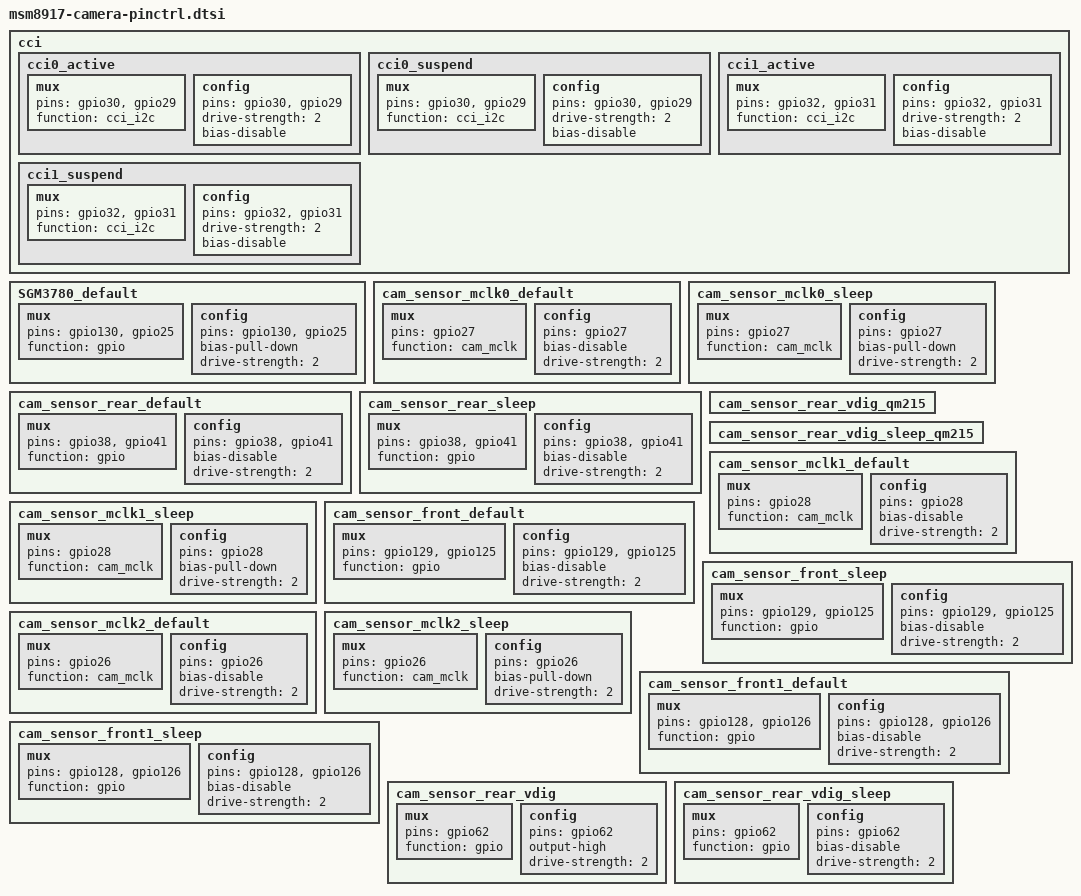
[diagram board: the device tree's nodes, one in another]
/*
 * Copyright (c) 2015, 2018, The Linux Foundation. All rights reserved.
 *
 * This program is free software; you can redistribute it and/or modify
 * it under the terms of the GNU General Public License version 2 and
 * only version 2 as published by the Free Software Foundation.
 *
 * This program is distributed in the hope that it will be useful,
 * but WITHOUT ANY WARRANTY; without even the implied warranty of
 * MERCHANTABILITY or FITNESS FOR A PARTICULAR PURPOSE.  See the
 * GNU General Public License for more details.
 */

cci {
	cci0_active: cci0_active {
		/* cci0 active state */
		mux {
			/* CLK, DATA */
			pins = "gpio30", "gpio29";
			function = "cci_i2c";
		};

		config {
			pins = "gpio30", "gpio29";
			drive-strength = <2>; /* 2 MA */
			bias-disable; /* No PULL */
		};
	};

	cci0_suspend: cci0_suspend {
		/* cci0 suspended state */
		mux {
			/* CLK, DATA */
			pins = "gpio30", "gpio29";
			function = "cci_i2c";
		};

		config {
			pins = "gpio30", "gpio29";
			drive-strength = <2>; /* 2 MA */
			bias-disable; /* No PULL */
		};
	};

	cci1_active: cci1_active {
		/* cci1 active state */
		mux {
			/* CLK, DATA */
			pins = "gpio32", "gpio31";
			function = "cci_i2c";
		};

		config {
			pins = "gpio32", "gpio31";
			drive-strength = <2>; /* 2 MA */
			bias-disable; /* No PULL */
		};
	};

	cci1_suspend: cci1_suspend {
		/* cci1 suspended state */
		mux {
			/* CLK, DATA */
			pins = "gpio32", "gpio31";
			function = "cci_i2c";
		};

		config {
			pins = "gpio32", "gpio31";
			drive-strength = <2>; /* 2 MA */
			bias-disable; /* No PULL */
		};
	};
};

/*sensors */

/*flashlight*/
SGM3780_default: SGM3780_default {
			mux {
				/* CLK, DATA */
				pins = "gpio130", "gpio25";
				function = "gpio";
			};

			config {
				pins = "gpio130", "gpio25";
				//bias-disable; /* No PULL */
				bias-pull-down;
				drive-strength = <2>; /* 2 MA */
			};
		};


/*Main Camera*/
cam_sensor_mclk0_default: cam_sensor_mclk0_default {
	/* MCLK0 */
	mux {
		/* CLK, DATA */
		pins = "gpio27";
		function = "cam_mclk";
	};

	config {
		pins = "gpio27";
		bias-disable; /* No PULL */
		drive-strength = <2>; /* 2 MA */
	};
};

cam_sensor_mclk0_sleep: cam_sensor_mclk0_sleep {
	/* MCLK0 */
	mux {
		/* CLK, DATA */
		pins = "gpio27";
		function = "cam_mclk";
	};

	config {
		pins = "gpio27";
		bias-pull-down; /* PULL DOWN */
		drive-strength = <2>; /* 2 MA */
	};
};

cam_sensor_rear_default: cam_sensor_rear_default {
	/* RESET, STANDBY */
	mux {
		pins = "gpio38", "gpio41";
		function = "gpio";
	};

	config {
		pins = "gpio38","gpio41";
		bias-disable; /* No PULL */
		drive-strength = <2>; /* 2 MA */
	};
};

cam_sensor_rear_sleep: cam_sensor_rear_sleep {
	/* RESET, STANDBY */
	mux {
		pins = "gpio38","gpio41";
		function = "gpio";
	};

	config {
		pins = "gpio38","gpio41";
		bias-disable; /* No PULL */
		drive-strength = <2>; /* 2 MA */
	};
};

cam_sensor_rear_vdig_qm215: cam_sensor_rear_vdig_qm215 {
	/* VDIG */
	// mux {
	// 	pins = "gpio94";
	// 	function = "gpio";
	// };

	// config {
	// 	pins = "gpio94";
	// 	//output-high;
	// 	output-low;
	// 	drive-strength = <2>; /* 2 MA */
	// };
};

cam_sensor_rear_vdig_sleep_qm215: cam_sensor_rear_vdig_sleep_qm215 {
	/* VDIG */
	// mux {
	// 	pins = "gpio94";
	// 	function = "gpio";
	// };

	// config {
	// 	pins = "gpio94";
	// 	//output-low;
	// 	bias-disable; /* No PULL */
	// 	drive-strength = <2>; /* 2 MA */
	// };
};

/*Depth Camera*/
cam_sensor_mclk1_default: cam_sensor_mclk1_default {
	/* MCLK1 */
	mux {
		/* CLK, DATA */
		pins = "gpio28";  //28
		function = "cam_mclk";
	};

	config {
		pins = "gpio28";
		bias-disable; /* No PULL */
		drive-strength = <2>; /* 2 MA */
	};
};

cam_sensor_mclk1_sleep: cam_sensor_mclk1_sleep {
	/* MCLK1 */
	mux {
		/* CLK, DATA */
		pins = "gpio28";
		function = "cam_mclk";
	};

	config {
		pins = "gpio28";
		bias-pull-down; /* PULL DOWN */
		drive-strength = <2>; /* 2 MA */
	};
};

cam_sensor_front_default: cam_sensor_front_default {
	/* RESET, STANDBY */
	mux {
		pins = "gpio129","gpio125";
		function = "gpio";
	};

	config {
		pins = "gpio129","gpio125";
		bias-disable; /* No PULL */
		drive-strength = <2>; /* 2 MA */
	};
};

cam_sensor_front_sleep: cam_sensor_front_sleep {
	/* RESET, STANDBY */
	mux {
		pins = "gpio129","gpio125";
		function = "gpio";
	};

	config {
		pins = "gpio129","gpio125";
		bias-disable; /* No PULL */
		drive-strength = <2>; /* 2 MA */
	};
};

/*Sub Camera*/
cam_sensor_mclk2_default: cam_sensor_mclk2_default {
	/* MCLK2 */
	mux {
		/* CLK, DATA */
		pins = "gpio26";
		function = "cam_mclk";
	};

	config {
		pins = "gpio26";
		bias-disable; /* No PULL */
		drive-strength = <2>; /* 2 MA */
	};
};

cam_sensor_mclk2_sleep: cam_sensor_mclk2_sleep {
	/* MCLK2 */
	mux {
		/* CLK, DATA */
		pins = "gpio26";
		function = "cam_mclk";
	};

	config {
		pins = "gpio26";
		bias-pull-down; /* PULL DOWN */
		drive-strength = <2>; /* 2 MA */
	};
};

cam_sensor_front1_default: cam_sensor_front1_default {
	/* RESET, STANDBY */
	mux {
		pins = "gpio128", "gpio126";
		function = "gpio";
	};

	config {
		pins = "gpio128", "gpio126";
		bias-disable; /* No PULL */
		drive-strength = <2>; /* 2 MA */
	};
};

cam_sensor_front1_sleep: cam_sensor_front1_sleep {
	/* RESET, STANDBY */
	mux {
		pins = "gpio128", "gpio126";
		function = "gpio";
	};

	config {
		pins = "gpio128", "gpio126";
		bias-disable; /* No PULL */
		drive-strength = <2>; /* 2 MA */
	};
};

cam_sensor_rear_vdig: cam_sensor_rear_vdig {
	/* VDIG */
	mux {
		pins = "gpio62";
		function = "gpio";
	};

	config {
		pins = "gpio62";
		output-high;
		drive-strength = <2>; /* 2 MA */
	};
};

cam_sensor_rear_vdig_sleep: cam_sensor_rear_vdig_sleep {
	/* VDIG */
	mux {
		pins = "gpio62";
		function = "gpio";
	};

	config {
		pins = "gpio62";
		bias-disable; /* No PULL */
		drive-strength = <2>; /* 2 MA */
	};
};



